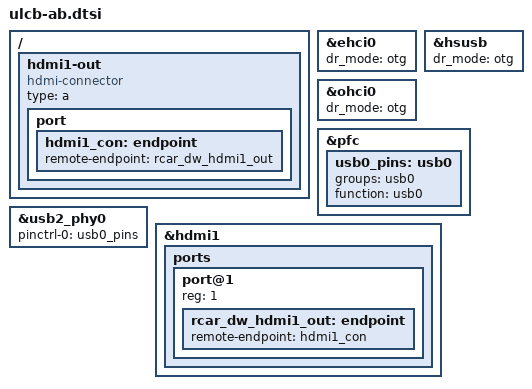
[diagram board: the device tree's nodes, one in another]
// SPDX-License-Identifier: GPL-2.0
/*
 * Device Tree Source for the Aos box (CCPF Starter kit) board
 *
 * Copyright (C) 2017-2021 Renesas Electronics Corp.
 * Copyright (C) 2021 EPAM Systems, Inc
 */

&ehci0 {
	dr_mode = "otg";
	status = "okay";
};

&hsusb {
	dr_mode = "otg";
	status = "okay";
};

&ohci0 {
	dr_mode = "otg";
	status = "okay";
};

&pfc {
	usb0_pins: usb0 {
		groups = "usb0";
		function = "usb0";
	};
};

&usb2_phy0 {
	pinctrl-0 = <&usb0_pins>;
	pinctrl-names = "default";

	status = "okay";
};

&hdmi1 {
	status = "okay";

	ports {
		port@1 {
			reg = <1>;
			rcar_dw_hdmi1_out: endpoint {
				remote-endpoint = <&hdmi1_con>;
			};
		};
	};
};

/ {
	hdmi1-out {
		compatible = "hdmi-connector";
		type = "a";

		port {
			hdmi1_con: endpoint {
	            remote-endpoint = <&rcar_dw_hdmi1_out>;
			};
		};
	};
};
